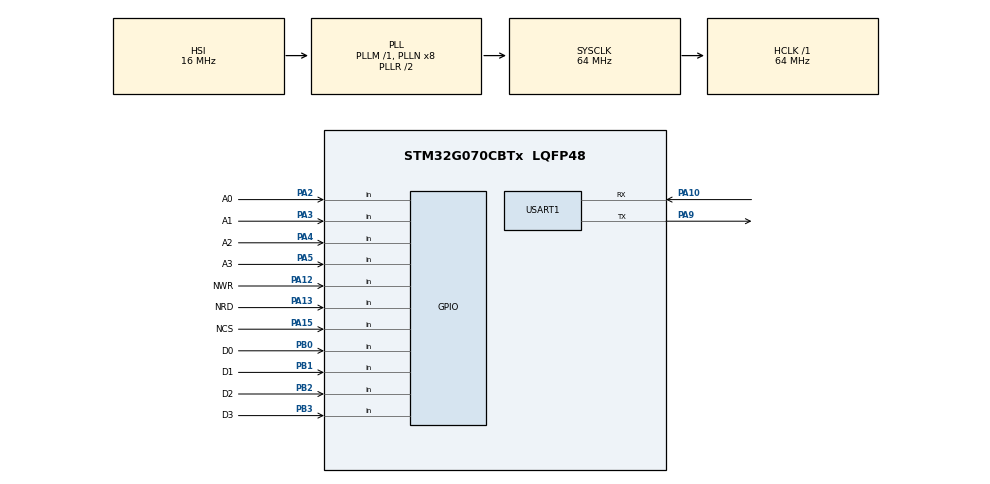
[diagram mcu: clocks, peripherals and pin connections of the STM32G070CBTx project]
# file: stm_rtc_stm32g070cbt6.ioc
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Mcu.Family=STM32G0
Mcu.Name=STM32G070CBTx
Mcu.Package=LQFP48
PA10.Mode=Asynchronous
PA10.Signal=USART1_RX
PA12\ [PA10].GPIO_Label=NWR
PA12\ [PA10].Signal=GPIO_Input
PA13.GPIO_Label=NRD
PA13.Signal=GPIO_Input
PA15.GPIO_Label=NCS
PA15.Signal=GPIO_Input
PA2.GPIO_Label=A0
PA2.Signal=GPIO_Input
PA3.GPIO_Label=A1
PA3.Signal=GPIO_Input
PA4.GPIO_Label=A2
PA4.Signal=GPIO_Input
PA5.GPIO_Label=A3
PA5.Signal=GPIO_Input
PA9.Mode=Asynchronous
PA9.Signal=USART1_TX
PB0.GPIO_Label=D0
PB0.Signal=GPIO_Input
PB1.GPIO_Label=D1
PB1.Signal=GPIO_Input
PB2.GPIO_Label=D2
PB2.Signal=GPIO_Input
PB3.GPIO_Label=D3
PB3.Signal=GPIO_Input
ProjectManager.HeapSize=0x200
ProjectManager.StackSize=0x400
ProjectManager.TargetToolchain=Makefile
RCC.ADCFreq_Value=64000000
RCC.AHBFreq_Value=64000000
RCC.CortexFreq_Value=64000000
RCC.DATA_CACHE_ENABLE=1
RCC.EXTERNAL_CLOCK_VALUE=48000
RCC.HCLKFreq_Value=64000000
RCC.HSE_VALUE=8000000
RCC.HSI_VALUE=16000000
RCC.INSTRUCTION_CACHE_ENABLE=1
RCC.LSE_VALUE=32768
RCC.PREFETCH_ENABLE=1
RCC.SYSCLKFreq_VALUE=64000000
RCC.SYSCLKSource=RCC_SYSCLKSOURCE_PLLCLK
RCC.VCOOutputFreq_Value=128000000
RTC.Date=23
RTC.Hours=13
RTC.Minutes=37
RTC.Month=RTC_MONTH_APRIL
RTC.Seconds=8
RTC.WeekDay=RTC_WEEKDAY_TUESDAY
RTC.Year=19
USART1.VirtualMode-Asynchronous=VM_ASYNC
VP_RTC_VS_RTC_Activate.Mode=RTC_Enabled
VP_RTC_VS_RTC_Calendar.Mode=RTC_Calendar
VP_SYS_VS_DBSignals.Mode=DisableDeadBatterySignals
board=custom

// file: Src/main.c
/* USER CODE BEGIN Header */
/**
  ******************************************************************************
  * @file           : main.c
  * @brief          : Main program body
  ******************************************************************************
  ** This notice applies to any and all portions of this file
  * that are not between comment pairs USER CODE BEGIN and
  * USER CODE END. Other portions of this file, whether
  * inserted by the user or by software development tools
  * are owned by their respective copyright owners.
  *
  * COPYRIGHT(c) 2018 STMicroelectronics
  *
  * Redistribution and use in source and binary forms, with or without modification,
  * are permitted provided that the following conditions are met:
  *   1. Redistributions of source code must retain the above copyright notice,
  *      this list of conditions and the following disclaimer.
  *   2. Redistributions in binary form must reproduce the above copyright notice,
  *      this list of conditions and the following disclaimer in the documentation
  *      and/or other materials provided with the distribution.
  *   3. Neither the name of STMicroelectronics nor the names of its contributors
  *      may be used to endorse or promote products derived from this software
  *      without specific prior written permission.
  *
  * THIS SOFTWARE IS PROVIDED BY THE COPYRIGHT HOLDERS AND CONTRIBUTORS "AS IS"
  * AND ANY EXPRESS OR IMPLIED WARRANTIES, INCLUDING, BUT NOT LIMITED TO, THE
  * IMPLIED WARRANTIES OF MERCHANTABILITY AND FITNESS FOR A PARTICULAR PURPOSE ARE
  * DISCLAIMED. IN NO EVENT SHALL THE COPYRIGHT HOLDER OR CONTRIBUTORS BE LIABLE
  * FOR ANY DIRECT, INDIRECT, INCIDENTAL, SPECIAL, EXEMPLARY, OR CONSEQUENTIAL
  * DAMAGES (INCLUDING, BUT NOT LIMITED TO, PROCUREMENT OF SUBSTITUTE GOODS OR
  * SERVICES; LOSS OF USE, DATA, OR PROFITS; OR BUSINESS INTERRUPTION) HOWEVER
  * CAUSED AND ON ANY THEORY OF LIABILITY, WHETHER IN CONTRACT, STRICT LIABILITY,
  * OR TORT (INCLUDING NEGLIGENCE OR OTHERWISE) ARISING IN ANY WAY OUT OF THE USE
  * OF THIS SOFTWARE, EVEN IF ADVISED OF THE POSSIBILITY OF SUCH DAMAGE.
  *
  ******************************************************************************
  */
/* USER CODE END Header */
#include "main.h"

/* USER CODE BEGIN Includes */
#include <string.h>
#include <errno.h>
#include <sys/unistd.h> // STDOUT_FILENO, STDERR_FILENO
#include "msm_rtc.h"
/* USER CODE END Includes */

RTC_HandleTypeDef hrtc;

UART_HandleTypeDef huart1;

void SystemClock_Config(void);
static void MX_GPIO_Init(void);
static void MX_RTC_Init(void);
static void MX_USART1_UART_Init(void);

/* USER CODE BEGIN 0 */

// Reimplementation of stdlib's _write for retargeting printf into UART 1
// https://electronics.stackexchange.com/questions/206113/
int _write(int file, char *data, int len) {
	if ((file != STDOUT_FILENO) && (file != STDERR_FILENO)) {
		errno = EBADF;
		return -1;
	}

	HAL_StatusTypeDef status = HAL_UART_Transmit(
		&huart1, (uint8_t*)data, len, HAL_MAX_DELAY
	);

	// return # of bytes written - as best we can tell
	return (status == HAL_OK ? len : 0);
}

/* USER CODE END 0 */

int main(void)
{

  /* MCU Configuration--------------------------------------------------------*/

  /* Reset of all peripherals, Initializes the Flash interface and the Systick. */
  HAL_Init();

  /* Configure the system clock */
  SystemClock_Config();

  /* Initialize all configured peripherals */
  MX_GPIO_Init();
  MX_RTC_Init();
  MX_USART1_UART_Init();
  /* USER CODE BEGIN 2 */

	msmRtcInit();

  /* USER CODE END 2 */

  /* Infinite loop */
  while (1)
  {

    /* USER CODE BEGIN 3 */
		msmRtcLoop();
	}
  /* USER CODE END 3 */
}

void SystemClock_Config(void)
{
  RCC_OscInitTypeDef RCC_OscInitStruct = {0};
  RCC_ClkInitTypeDef RCC_ClkInitStruct = {0};
  RCC_PeriphCLKInitTypeDef PeriphClkInit = {0};

  /** Configure the main internal regulator output voltage
  */
  HAL_PWREx_ControlVoltageScaling(PWR_REGULATOR_VOLTAGE_SCALE1);
  /** Initializes the RCC Oscillators according to the specified parameters
  * in the RCC_OscInitTypeDef structure.
  */
  RCC_OscInitStruct.OscillatorType = RCC_OSCILLATORTYPE_HSI|RCC_OSCILLATORTYPE_LSI;
  RCC_OscInitStruct.HSIState = RCC_HSI_ON;
  RCC_OscInitStruct.HSIDiv = RCC_HSI_DIV1;
  RCC_OscInitStruct.HSICalibrationValue = RCC_HSICALIBRATION_DEFAULT;
  RCC_OscInitStruct.LSIState = RCC_LSI_ON;
  RCC_OscInitStruct.PLL.PLLState = RCC_PLL_ON;
  RCC_OscInitStruct.PLL.PLLSource = RCC_PLLSOURCE_HSI;
  RCC_OscInitStruct.PLL.PLLM = RCC_PLLM_DIV1;
  RCC_OscInitStruct.PLL.PLLN = 8;
  RCC_OscInitStruct.PLL.PLLP = RCC_PLLP_DIV2;
  RCC_OscInitStruct.PLL.PLLR = RCC_PLLR_DIV2;
  if (HAL_RCC_OscConfig(&RCC_OscInitStruct) != HAL_OK)
  {
    Error_Handler();
  }
  /** Initializes the CPU, AHB and APB buses clocks
  */
  RCC_ClkInitStruct.ClockType = RCC_CLOCKTYPE_HCLK|RCC_CLOCKTYPE_SYSCLK
                              |RCC_CLOCKTYPE_PCLK1;
  RCC_ClkInitStruct.SYSCLKSource = RCC_SYSCLKSOURCE_PLLCLK;
  RCC_ClkInitStruct.AHBCLKDivider = RCC_SYSCLK_DIV1;
  RCC_ClkInitStruct.APB1CLKDivider = RCC_HCLK_DIV1;

  if (HAL_RCC_ClockConfig(&RCC_ClkInitStruct, FLASH_LATENCY_2) != HAL_OK)
  {
    Error_Handler();
  }
  /** Initializes the peripherals clocks
  */
  PeriphClkInit.PeriphClockSelection = RCC_PERIPHCLK_RTC|RCC_PERIPHCLK_USART1;
  PeriphClkInit.Usart1ClockSelection = RCC_USART1CLKSOURCE_PCLK1;
  PeriphClkInit.RTCClockSelection = RCC_RTCCLKSOURCE_LSI;

  if (HAL_RCCEx_PeriphCLKConfig(&PeriphClkInit) != HAL_OK)
  {
    Error_Handler();
  }
}

static void MX_RTC_Init(void)
{

  RTC_TimeTypeDef sTime = {0};
  RTC_DateTypeDef sDate = {0};

  /** Initialize RTC Only
  */
  hrtc.Instance = RTC;
  hrtc.Init.HourFormat = RTC_HOURFORMAT_24;
  hrtc.Init.AsynchPrediv = 127;
  hrtc.Init.SynchPrediv = 255;
  hrtc.Init.OutPut = RTC_OUTPUT_DISABLE;
  hrtc.Init.OutPutRemap = RTC_OUTPUT_REMAP_NONE;
  hrtc.Init.OutPutPolarity = RTC_OUTPUT_POLARITY_HIGH;
  hrtc.Init.OutPutType = RTC_OUTPUT_TYPE_OPENDRAIN;
  hrtc.Init.OutPutPullUp = RTC_OUTPUT_PULLUP_NONE;
  if (HAL_RTC_Init(&hrtc) != HAL_OK)
  {
    Error_Handler();
  }

  /** Initialize RTC and set the Time and Date
  */
  sTime.Hours = 0x13;
  sTime.Minutes = 0x37;
  sTime.Seconds = 0x8;
  sTime.SubSeconds = 0x0;
  sTime.DayLightSaving = RTC_DAYLIGHTSAVING_NONE;
  sTime.StoreOperation = RTC_STOREOPERATION_RESET;
  if (HAL_RTC_SetTime(&hrtc, &sTime, RTC_FORMAT_BCD) != HAL_OK)
  {
    Error_Handler();
  }
  sDate.WeekDay = RTC_WEEKDAY_TUESDAY;
  sDate.Month = RTC_MONTH_APRIL;
  sDate.Date = 0x23;
  sDate.Year = 0x19;

  if (HAL_RTC_SetDate(&hrtc, &sDate, RTC_FORMAT_BCD) != HAL_OK)
  {
    Error_Handler();
  }

}

static void MX_USART1_UART_Init(void)
{

  huart1.Instance = USART1;
  huart1.Init.BaudRate = 115200;
  huart1.Init.WordLength = UART_WORDLENGTH_8B;
  huart1.Init.StopBits = UART_STOPBITS_1;
  huart1.Init.Parity = UART_PARITY_NONE;
  huart1.Init.Mode = UART_MODE_TX_RX;
  huart1.Init.HwFlowCtl = UART_HWCONTROL_NONE;
  huart1.Init.OverSampling = UART_OVERSAMPLING_16;
  huart1.Init.OneBitSampling = UART_ONE_BIT_SAMPLE_DISABLE;
  huart1.Init.ClockPrescaler = UART_PRESCALER_DIV1;
  huart1.AdvancedInit.AdvFeatureInit = UART_ADVFEATURE_NO_INIT;
  if (HAL_UART_Init(&huart1) != HAL_OK)
  {
    Error_Handler();
  }
  if (HAL_UARTEx_SetTxFifoThreshold(&huart1, UART_TXFIFO_THRESHOLD_1_8) != HAL_OK)
  {
    Error_Handler();
  }
  if (HAL_UARTEx_SetRxFifoThreshold(&huart1, UART_RXFIFO_THRESHOLD_1_8) != HAL_OK)
  {
    Error_Handler();
  }
  if (HAL_UARTEx_DisableFifoMode(&huart1) != HAL_OK)
  {
    Error_Handler();
  }

}

static void MX_GPIO_Init(void)
{
  GPIO_InitTypeDef GPIO_InitStruct = {0};

  /* GPIO Ports Clock Enable */
  __HAL_RCC_GPIOA_CLK_ENABLE();
  __HAL_RCC_GPIOB_CLK_ENABLE();

  /*Configure GPIO pins : A0_Pin A1_Pin A2_Pin A3_Pin
                           NWR_Pin NRD_Pin NCS_Pin */
  GPIO_InitStruct.Pin = A0_Pin|A1_Pin|A2_Pin|A3_Pin
                          |NWR_Pin|NRD_Pin|NCS_Pin;
  GPIO_InitStruct.Mode = GPIO_MODE_INPUT;
  GPIO_InitStruct.Pull = GPIO_NOPULL;
  HAL_GPIO_Init(GPIOA, &GPIO_InitStruct);

  /*Configure GPIO pins : D0_Pin D1_Pin D2_Pin D3_Pin */
  GPIO_InitStruct.Pin = D0_Pin|D1_Pin|D2_Pin|D3_Pin;
  GPIO_InitStruct.Mode = GPIO_MODE_INPUT;
  GPIO_InitStruct.Pull = GPIO_NOPULL;
  HAL_GPIO_Init(GPIOB, &GPIO_InitStruct);

}

void Error_Handler(void)
{
}

/************************ (C) COPYRIGHT STMicroelectronics *****END OF FILE****/
